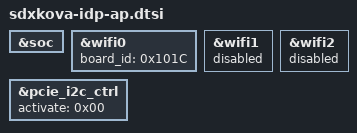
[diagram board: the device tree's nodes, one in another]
// SPDX-License-Identifier: BSD-3-Clause
/*
 * Copyright (c) Qualcomm Technologies, Inc. and/or its subsidiaries.
 */
#include "sdxkova-idp-cpe-v7.dtsi"
&soc {
};

/* Override board_id for dualmac AP configuration */
&wifi0 {
	board_id = <0x101C>;
};

&wifi1 {
	status = "disabled";
};

&wifi2 {
	status = "disabled";
};

&pcie_i2c_ctrl {
		activate = /bits/ 8 <0x00>;
	};

